# ESP32-H21 register map
Vendor: ESPRESSIF SYSTEMS (SHANGHAI) CO., LTD.; Series: ESP32 H-Series; File version: 1
CPU: RV32IMAC r0p0, little endian, no MPU, no FPU, 0 interrupt priority bits
Address unit: 32 bits
Registers are 32-bit, read-write, reset 0x0 unless marked. A register's access mark holds for its fields unless they carry their own. Offsets are from the block's base; [hi:lo] are bit positions; {n}, {i} and the like mark numbered series.

## INTPRI — INTPRI Peripheral
Base 0x600C5000
0x00 CPU_INT_ENABLE — register description
  [31:0] CPU_INT_ENABLE — Need add description
0x04 CPU_INT_TYPE — register description
  [31:0] CPU_INT_TYPE — Need add description
0x08 CPU_INT_EIP_STATUS ro — register description
  [31:0] CPU_INT_EIP_STATUS — Need add description
{0xC+4i} CPU_INT_PRI{i} (i=0..31) — register description
  [3:0] MAP — Need add description
0x8C CPU_INT_THRESH — register description
  [7:0] CPU_INT_THRESH — Need add description
{0x90+4i} CPU_INTR_FROM_CPU{i} (i=0..3) — register description
  [0] CPU_INTR — Need add description
0xA0 DATE — register description
0xA4 CLOCK_GATE reset 0x1 — register description
  [0] CLK_EN — Need add description
0xA8 CPU_INT_CLEAR — register description
  [31:0] CPU_INT_CLEAR — Need add description
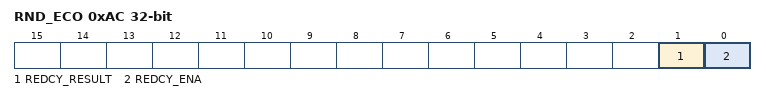
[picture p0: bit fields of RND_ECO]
0xAC RND_ECO access per field — redcy eco register.
  [1] REDCY_RESULT ro — Only reserved for ECO.
  [0] REDCY_ENA rw — Only reserved for ECO.
0xB0 RND_ECO_LOW — redcy eco low register.
  [31:0] REDCY_LOW — Only reserved for ECO.
0x3FC RND_ECO_HIGH reset 0xFFFFFFFF — redcy eco high register.
  [31:0] REDCY_HIGH — Only reserved for ECO.

## IO_MUX — Input/Output Multiplexer
Base 0x60090000
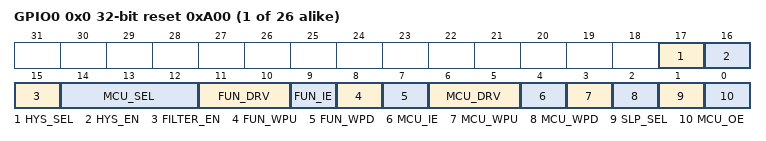
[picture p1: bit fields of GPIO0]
{0x0+4i} GPIO{i} (i=0..25) reset 0xA00 — IO_MUX Configure Registers for different pads
  [17] HYS_SEL — Select enabling signals of the pad from software and efuse hardware. 1: Select enabling siganl from slftware. 0: Select enabling signal from efuse hardware.
  [16] HYS_EN — Software enables hysteresis function for the pad. 1: Hysteresis enabled. 0: Hysteresis disabled.
  [15] FILTER_EN — Enable filter for pin input signals. 1: Filter enabled. 0: Filter disabled.
  [14:12] MCU_SEL — Select IO MUX function for this signal. 0: Select Function 1. 1: Select Function 2. etc.
  [11:10] FUN_DRV — Select the drive strength of the pad. 0: ~5 mA. 1: ~10mA. 2: ~20mA. 3: ~40mA.
  [9] FUN_IE — Input enable of the pad. 1: input enabled. 0: input disabled.
  [8] FUN_WPU — Pull-up enable of the pad. 1: internal pull-up enabled. 0: internal pull-up disabled.
  [7] FUN_WPD — Pull-down enable of the pad. 1: internal pull-down enabled. 0: internal pull-down disabled.
  [6:5] MCU_DRV — Select the drive strength of the pad during sleep mode. 0: ~5 mA. 1: ~10mA. 2: ~20mA. 3: ~40mA.
  [4] MCU_IE — Input enable of the pad during sleep mode. 1: input enabled. 0: input disabled.
  [3] MCU_WPU — Pull-up enable of the pad during sleep mode. 1: internal pull-up enabled. 0: internal pull-up disabled.
  [2] MCU_WPD — Pull-down enable of the pad in sleep mode. 1: internal pull-down enabled. 0: internal pull-down disabled.
  [1] SLP_SEL — Sleep mode selection of this pad. Set to 1 to put the pad in pad mode.
  [0] MCU_OE — Output enable of the pad in sleep mode. 1: output enabled. 0: output disabled.
0x1FC DATE — IO_MUX Version Control Register

## LP_PERI — LP_PERI Peripheral
Base 0x600B2800
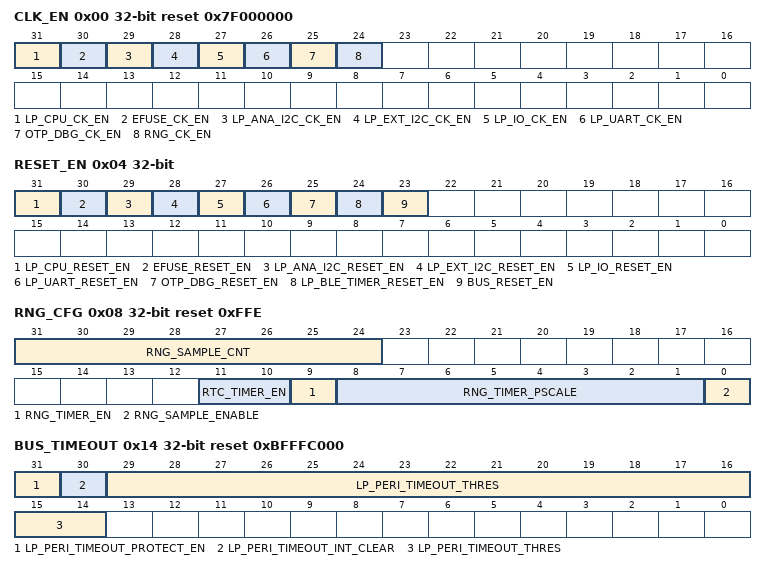
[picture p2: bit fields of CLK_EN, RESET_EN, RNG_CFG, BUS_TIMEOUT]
0x00 CLK_EN reset 0x7F000000 — need_des
  [31] LP_CPU_CK_EN — need_des
  [30] EFUSE_CK_EN — need_des
  [29] LP_ANA_I2C_CK_EN — need_des
  [28] LP_EXT_I2C_CK_EN — need_des
  [27] LP_IO_CK_EN — need_des
  [26] LP_UART_CK_EN — need_des
  [25] OTP_DBG_CK_EN — need_des
  [24] RNG_CK_EN — need_des
0x04 RESET_EN access per field — need_des
  [31] LP_CPU_RESET_EN wo — need_des
  [30] EFUSE_RESET_EN rw — need_des
  [29] LP_ANA_I2C_RESET_EN rw — need_des
  [28] LP_EXT_I2C_RESET_EN rw — need_des
  [27] LP_IO_RESET_EN rw — need_des
  [26] LP_UART_RESET_EN rw — need_des
  [25] OTP_DBG_RESET_EN rw — need_des
  [24] LP_BLE_TIMER_RESET_EN rw — need_des
  [23] BUS_RESET_EN wo — need_des
0x08 RNG_CFG access per field reset 0xFFE — need_des
  [31:24] RNG_SAMPLE_CNT ro — need des
  [11:10] RTC_TIMER_EN rw — need des
  [9] RNG_TIMER_EN rw — need des
  [8:1] RNG_TIMER_PSCALE rw — need des
  [0] RNG_SAMPLE_ENABLE rw — need des
0x10 CPU reset 0x80000000 — need_des
  [31] LPCORE_DBGM_UNAVALIABLE
0x14 BUS_TIMEOUT access per field reset 0xBFFFC000 — need_des
  [31] LP_PERI_TIMEOUT_PROTECT_EN rw — need_des
  [30] LP_PERI_TIMEOUT_INT_CLEAR wo — need_des
  [29:14] LP_PERI_TIMEOUT_THRES rw — need_des
0x18 BUS_TIMEOUT_ADDR ro — need_des
  [31:0] LP_PERI_TIMEOUT_ADDR
0x1C BUS_TIMEOUT_UID ro — need_des
  [6:0] LP_PERI_TIMEOUT_UID
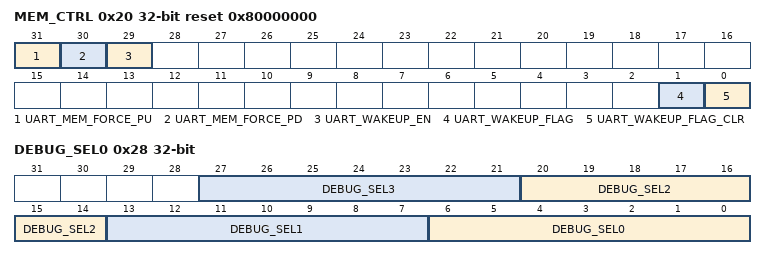
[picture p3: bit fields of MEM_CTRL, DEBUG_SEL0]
0x20 MEM_CTRL access per field reset 0x80000000 — need_des
  [31] UART_MEM_FORCE_PU rw — need_des
  [30] UART_MEM_FORCE_PD rw — need_des
  [29] UART_WAKEUP_EN rw — need_des
  [1] UART_WAKEUP_FLAG rw — need_des
  [0] UART_WAKEUP_FLAG_CLR wo — need_des
0x24 INTERRUPT_SOURCE ro — need_des
  [5:0] LP_INTERRUPT_SOURCE — BIT5~BIT0: pmu_lp_int, modem_lp_int, lp_timer_lp_int, lp_uart_int, lp_i2c_int, lp_io_int
0x28 DEBUG_SEL0 — need des
  [7n+6:7n] DEBUG_SEL{n} (n=0..3) — need des
0x2C DEBUG_SEL1 — need des
  [6:0] DEBUG_SEL4
0x30 RNG_DATA ro — rng result sync register
  [31:0] RND_SYNC_DATA — get rng sync result
0x3FC DATE — need_des
